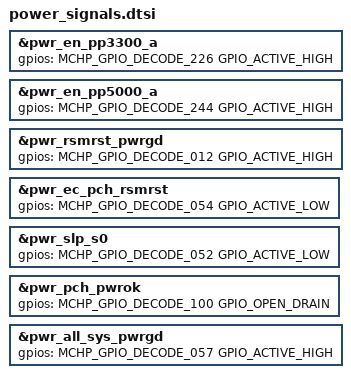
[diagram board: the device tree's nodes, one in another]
/* Copyright 2025 The ChromiumOS Authors
 * Use of this source code is governed by a BSD-style license that can be
 * found in the LICENSE file.
 */

#include "../power_signals.dtsi"

&pwr_en_pp3300_a {
	gpios = <MCHP_GPIO_DECODE_226 GPIO_ACTIVE_HIGH>;
};
&pwr_en_pp5000_a {
	gpios = <MCHP_GPIO_DECODE_244 GPIO_ACTIVE_HIGH>;
};
&pwr_rsmrst_pwrgd {
	gpios = <MCHP_GPIO_DECODE_012 GPIO_ACTIVE_HIGH>;
};
&pwr_ec_pch_rsmrst {
	gpios = <MCHP_GPIO_DECODE_054 GPIO_ACTIVE_LOW>;
};
&pwr_slp_s0 {
	gpios = <MCHP_GPIO_DECODE_052 GPIO_ACTIVE_LOW>;
};
&pwr_pch_pwrok {
	gpios = <MCHP_GPIO_DECODE_100 GPIO_OPEN_DRAIN>;
};
&pwr_all_sys_pwrgd {
	gpios = <MCHP_GPIO_DECODE_057 GPIO_ACTIVE_HIGH>;
};
